# PIC32MZ2048EFM144 register map
Registers are 32-bit, access not given, reset 0x0 unless marked. A register's access mark holds for its fields unless they carry their own. Offsets are from the block's base; [hi:lo] are bit positions; {n}, {i} and the like mark numbered series; 'fields as' and 'values as' point back to an identical list.

## DMT — DMT peripheral
Base 0xBF800A00
0x00 DMTCON
  [15] ON
0x10 DMTPRECLR
  [15:8] STEP1
0x20 DMTCLR
  [7:0] STEP2
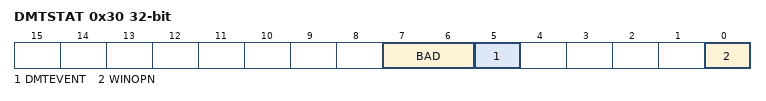
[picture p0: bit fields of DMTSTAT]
0x30 DMTSTAT
  [7:6] BAD, [5] DMTEVENT, [0] WINOPN
0x40 DMTCNT
  [31:0] COUNTER
0x60 DMTPSCNT
  [31:0] PSCNT
0x70 DMTPSINTV
  [31:0] PSINTV

## RTCC — RTCC peripheral
Base 0xBF800C00
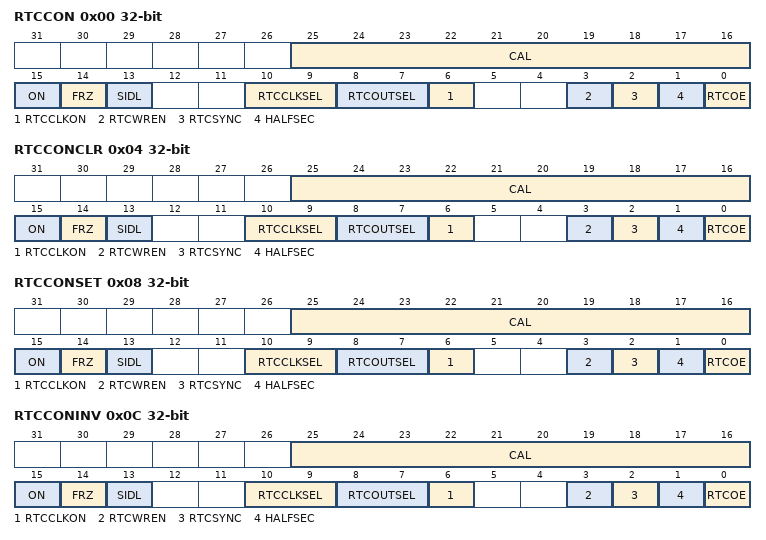
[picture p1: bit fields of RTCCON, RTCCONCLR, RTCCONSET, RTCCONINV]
0x00 RTCCON
  [25:16] CAL, [15] ON, [14] FRZ, [13] SIDL, [10:9] RTCCLKSEL, [8:7] RTCOUTSEL, [6] RTCCLKON, [3] RTCWREN, [2] RTCSYNC, [1] HALFSEC, [0] RTCOE
0x04 RTCCONCLR
  fields as RTCCON
0x08 RTCCONSET
  fields as RTCCON
0x0C RTCCONINV
  fields as RTCCON
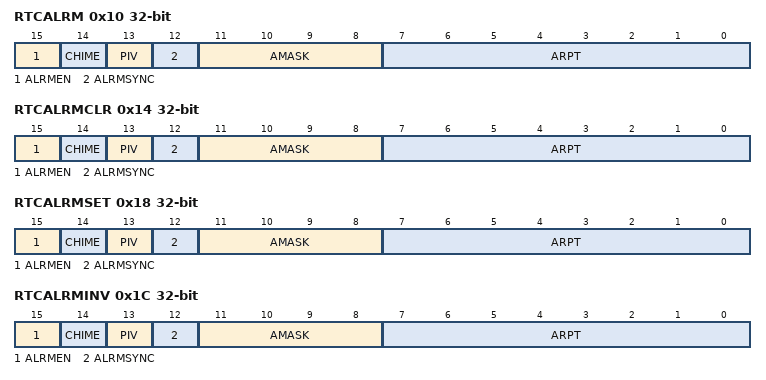
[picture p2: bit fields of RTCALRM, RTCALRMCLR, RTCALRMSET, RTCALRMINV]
0x10 RTCALRM
  [15] ALRMEN, [14] CHIME, [13] PIV, [12] ALRMSYNC, [11:8] AMASK, [7:0] ARPT
0x14 RTCALRMCLR
  fields as RTCALRM
0x18 RTCALRMSET
  fields as RTCALRM
0x1C RTCALRMINV
  fields as RTCALRM
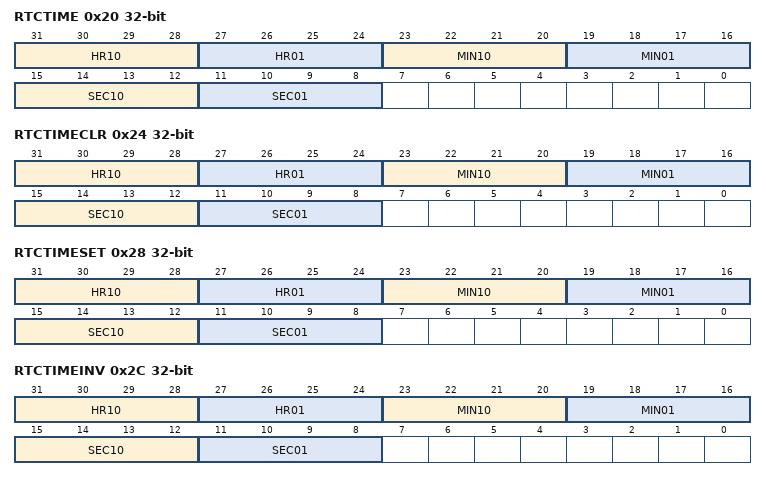
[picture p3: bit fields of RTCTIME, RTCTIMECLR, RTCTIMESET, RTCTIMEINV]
0x20 RTCTIME
  [31:28] HR10, [27:24] HR01, [23:20] MIN10, [19:16] MIN01, [15:12] SEC10, [11:8] SEC01
0x24 RTCTIMECLR
  fields as RTCTIME
0x28 RTCTIMESET
  fields as RTCTIME
0x2C RTCTIMEINV
  fields as RTCTIME
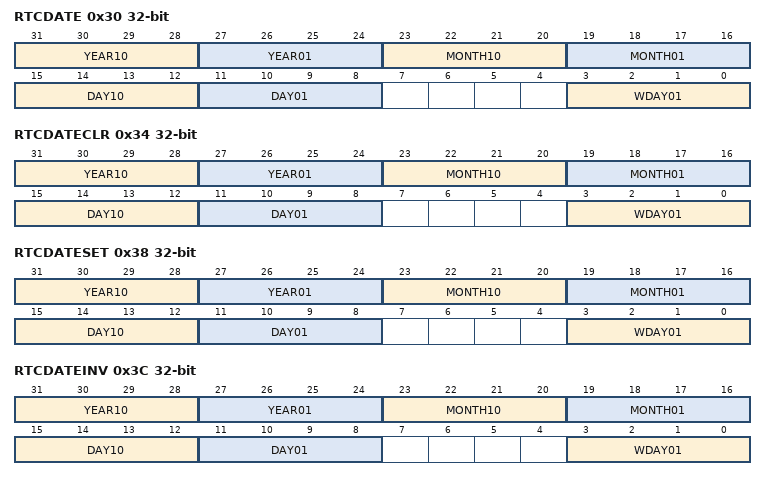
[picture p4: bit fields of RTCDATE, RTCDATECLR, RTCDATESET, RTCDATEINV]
0x30 RTCDATE
  [31:28] YEAR10, [27:24] YEAR01, [23:20] MONTH10, [19:16] MONTH01, [15:12] DAY10, [11:8] DAY01, [3:0] WDAY01
0x34 RTCDATECLR
  fields as RTCDATE
0x38 RTCDATESET
  fields as RTCDATE
0x3C RTCDATEINV
  fields as RTCDATE
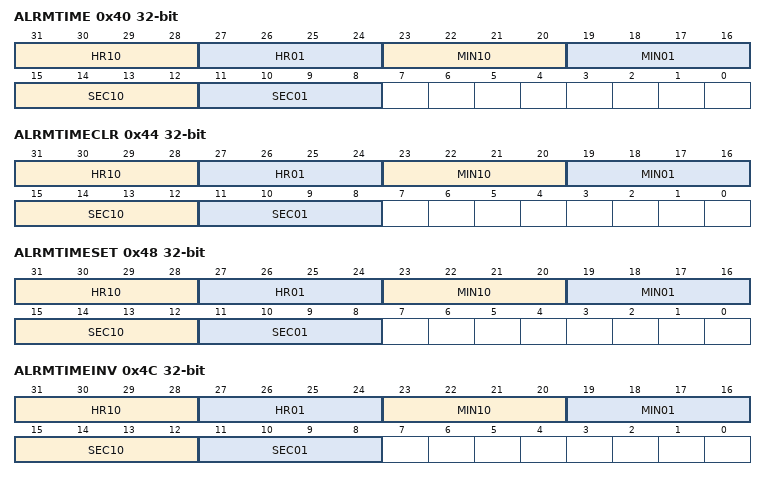
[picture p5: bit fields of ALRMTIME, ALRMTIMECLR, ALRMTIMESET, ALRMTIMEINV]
0x40 ALRMTIME
  fields as RTCTIME
0x44 ALRMTIMECLR
  fields as RTCTIME
0x48 ALRMTIMESET
  fields as RTCTIME
0x4C ALRMTIMEINV
  fields as RTCTIME
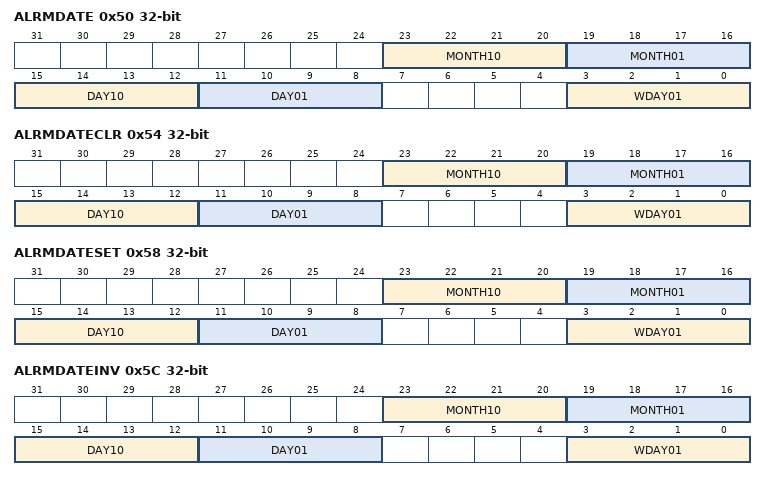
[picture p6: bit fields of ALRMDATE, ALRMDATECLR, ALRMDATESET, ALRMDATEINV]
0x50 ALRMDATE
  [23:20] MONTH10, [19:16] MONTH01, [15:12] DAY10, [11:8] DAY01, [3:0] WDAY01
0x54 ALRMDATECLR
  fields as ALRMDATE
0x58 ALRMDATESET
  fields as ALRMDATE
0x5C ALRMDATEINV
  fields as ALRMDATE

## CVR — CVR peripheral
Base 0xBF800E00
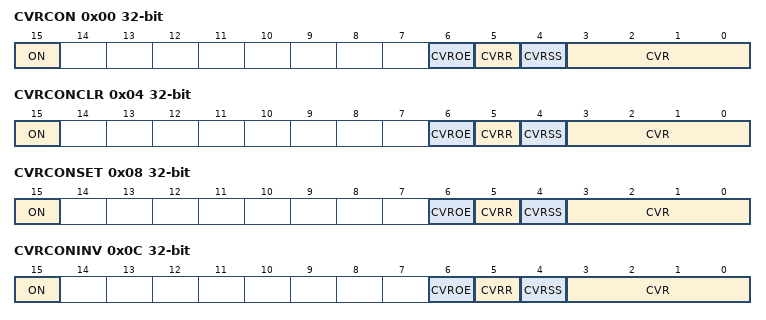
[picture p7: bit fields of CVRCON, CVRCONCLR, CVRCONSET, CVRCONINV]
0x00 CVRCON
  [15] ON, [6] CVROE, [5] CVRR, [4] CVRSS, [3:0] CVR
0x04 CVRCONCLR
  [15] ON, [6] CVROE, [5] CVRR, [4] CVRSS, [3:0] CVR
0x08 CVRCONSET
  [15] ON, [6] CVROE, [5] CVRR, [4] CVRSS, [3:0] CVR
0x0C CVRCONINV
  [15] ON, [6] CVROE, [5] CVRR, [4] CVRSS, [3:0] CVR

## ICD — ICD peripheral
Base 0xBF801130
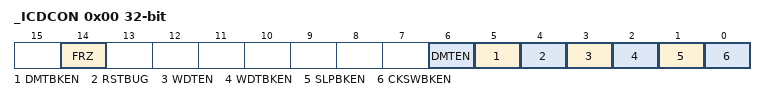
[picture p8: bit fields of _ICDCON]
0x00 _ICDCON
  [14] FRZ, [6] DMTEN, [5] DMTBKEN, [4] RSTBUG, [3] WDTEN, [2] WDTBKEN, [1] SLPBKEN, [0] CKSWBKEN

## _DDPSTAT — _DDPSTAT peripheral
Base 0xBF801140
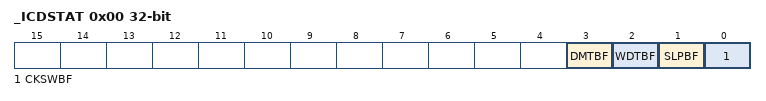
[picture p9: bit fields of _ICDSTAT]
0x00 _ICDSTAT
  [3] DMTBF, [2] WDTBF, [1] SLPBF, [0] CKSWBF

## CRU — CRU peripheral
Base 0xBF801200
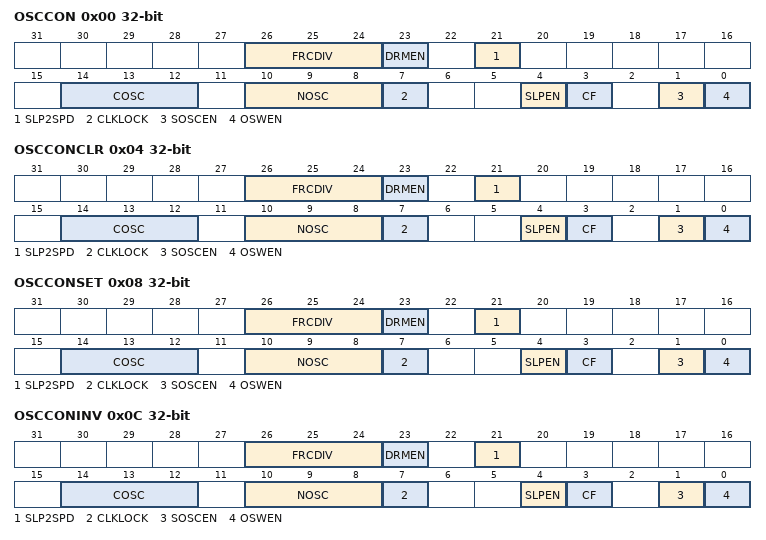
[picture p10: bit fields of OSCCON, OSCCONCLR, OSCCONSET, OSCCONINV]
0x00 OSCCON
  [26:24] FRCDIV, [23] DRMEN, [21] SLP2SPD, [14:12] COSC, [10:8] NOSC, [7] CLKLOCK, [4] SLPEN, [3] CF, [1] SOSCEN, [0] OSWEN
0x04 OSCCONCLR
  fields as OSCCON
0x08 OSCCONSET
  fields as OSCCON
0x0C OSCCONINV
  fields as OSCCON
0x10 OSCTUN
  [5:0] TUN
0x14 OSCTUNCLR
  [5:0] TUN
0x18 OSCTUNSET
  [5:0] TUN
0x1C OSCTUNINV
  [5:0] TUN
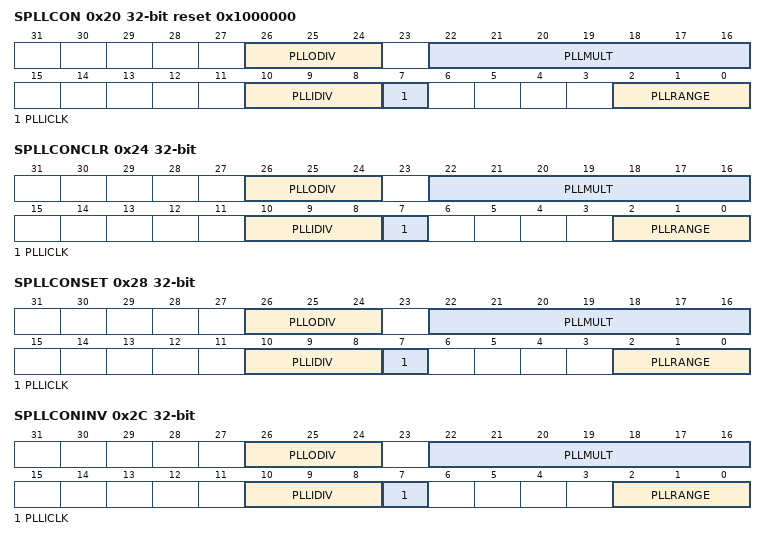
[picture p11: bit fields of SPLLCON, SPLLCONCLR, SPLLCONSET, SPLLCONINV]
0x20 SPLLCON reset 0x1000000
  [26:24] PLLODIV, [22:16] PLLMULT, [10:8] PLLIDIV, [7] PLLICLK, [2:0] PLLRANGE
0x24 SPLLCONCLR
  fields as SPLLCON
0x28 SPLLCONSET
  fields as SPLLCON
0x2C SPLLCONINV
  fields as SPLLCON
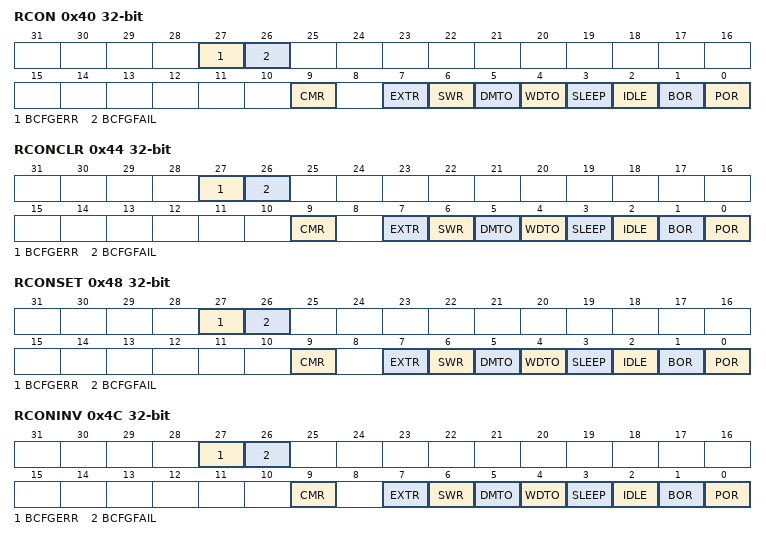
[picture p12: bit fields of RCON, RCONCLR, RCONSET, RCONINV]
0x40 RCON
  [27] BCFGERR, [26] BCFGFAIL, [9] CMR, [7] EXTR, [6] SWR, [5] DMTO, [4] WDTO, [3] SLEEP, [2] IDLE, [1] BOR, [0] POR
0x44 RCONCLR
  fields as RCON
0x48 RCONSET
  fields as RCON
0x4C RCONINV
  fields as RCON
0x50 RSWRST
  [0] SWRST
0x54 RSWRSTCLR
  [0] SWRST
0x58 RSWRSTSET
  [0] SWRST
0x5C RSWRSTINV
  [0] SWRST
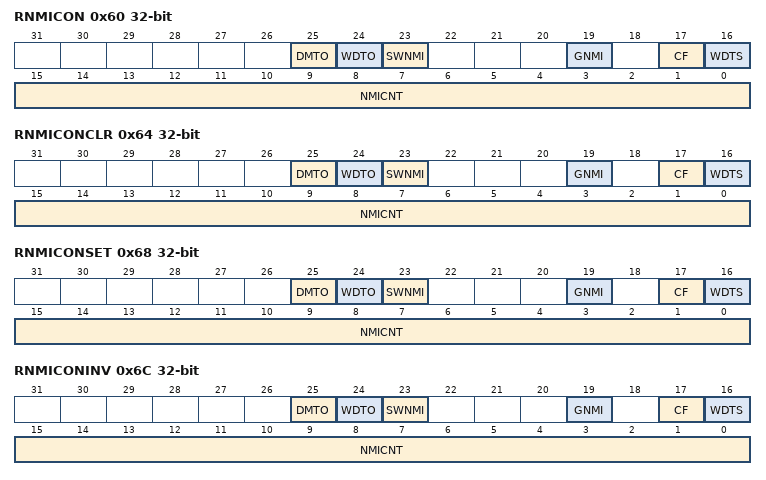
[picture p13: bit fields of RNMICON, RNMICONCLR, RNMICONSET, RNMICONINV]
0x60 RNMICON
  [25] DMTO, [24] WDTO, [23] SWNMI, [19] GNMI, [17] CF, [16] WDTS, [15:0] NMICNT
0x64 RNMICONCLR
  fields as RNMICON
0x68 RNMICONSET
  fields as RNMICON
0x6C RNMICONINV
  fields as RNMICON
0x70 PWRCON
  [0] VREGS
0x74 PWRCONCLR
  [0] VREGS
0x78 PWRCONSET
  [0] VREGS
0x7C PWRCONINV
  [0] VREGS
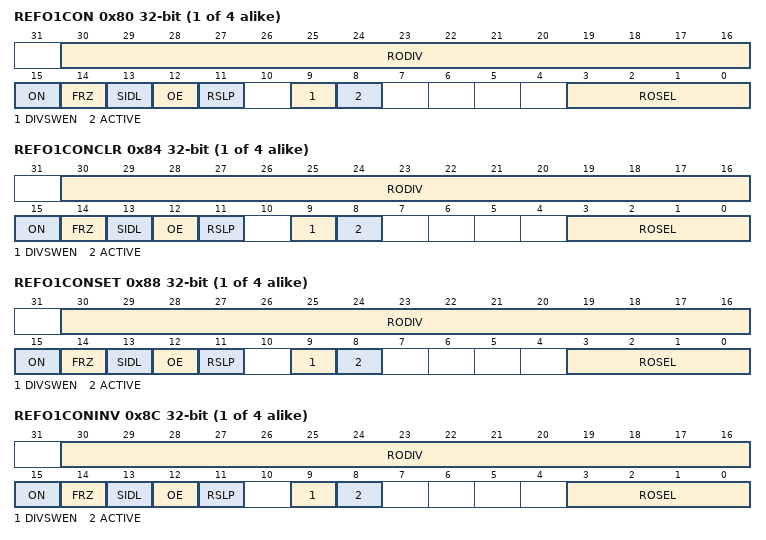
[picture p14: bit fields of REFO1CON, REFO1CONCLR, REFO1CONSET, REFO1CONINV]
{0x60+0x20*i} REFO{i}CON (i=1..4)
  [30:16] RODIV, [15] ON, [14] FRZ, [13] SIDL, [12] OE, [11] RSLP, [9] DIVSWEN, [8] ACTIVE, [3:0] ROSEL
{0x64+0x20*i} REFO{i}CONCLR (i=1..4)
  fields as REFO1CON
{0x68+0x20*i} REFO{i}CONSET (i=1..4)
  fields as REFO1CON
{0x6C+0x20*i} REFO{i}CONINV (i=1..4)
  fields as REFO1CON
{0x70+0x20*i} REFO{i}TRIM (i=1..4)
  [31:23] ROTRIM
{0x74+0x20*i} REFO{i}TRIMCLR (i=1..4)
  [31:23] ROTRIM
{0x78+0x20*i} REFO{i}TRIMSET (i=1..4)
  [31:23] ROTRIM
{0x7C+0x20*i} REFO{i}TRIMINV (i=1..4)
  [31:23] ROTRIM
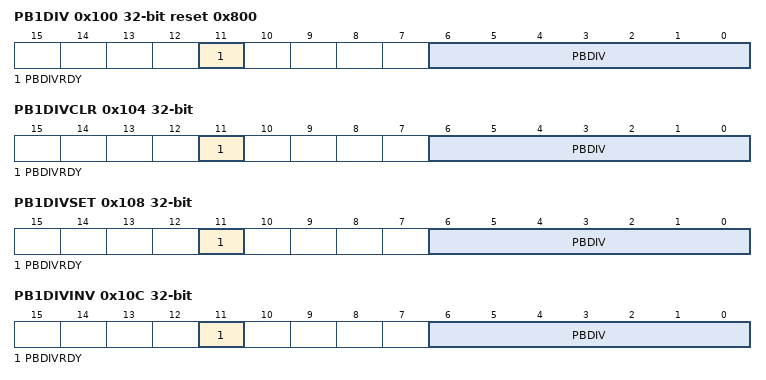
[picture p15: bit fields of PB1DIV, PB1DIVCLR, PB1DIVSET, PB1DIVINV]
0x100 PB1DIV reset 0x800
  [11] PBDIVRDY, [6:0] PBDIV
0x104 PB1DIVCLR
  [11] PBDIVRDY, [6:0] PBDIV
0x108 PB1DIVSET
  [11] PBDIVRDY, [6:0] PBDIV
0x10C PB1DIVINV
  [11] PBDIVRDY, [6:0] PBDIV
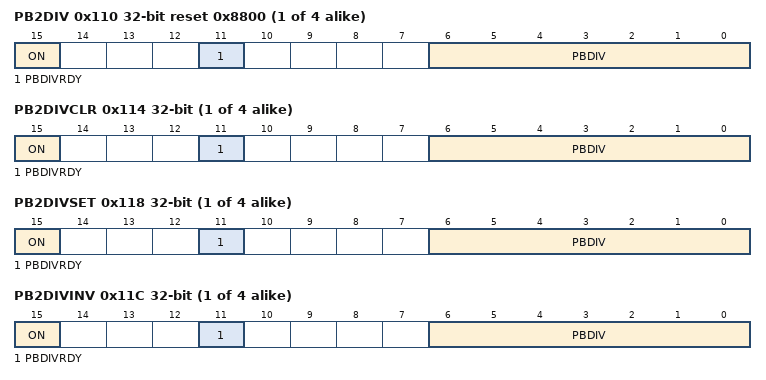
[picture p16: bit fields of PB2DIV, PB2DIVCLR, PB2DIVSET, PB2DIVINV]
{0xF0+0x10*i} PB{i}DIV reset 0x8800 (i=2..5)
  [15] ON, [11] PBDIVRDY, [6:0] PBDIV
{0xF4+0x10*i} PB{i}DIVCLR (i=2..5)
  [15] ON, [11] PBDIVRDY, [6:0] PBDIV
{0xF8+0x10*i} PB{i}DIVSET (i=2..5)
  [15] ON, [11] PBDIVRDY, [6:0] PBDIV
{0xFC+0x10*i} PB{i}DIVINV (i=2..5)
  [15] ON, [11] PBDIVRDY, [6:0] PBDIV
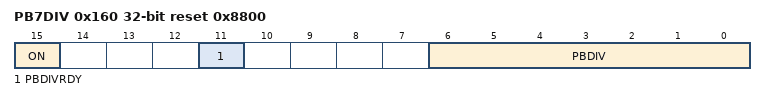
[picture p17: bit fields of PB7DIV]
0x160 PB7DIV reset 0x8800
  [15] ON, [11] PBDIVRDY, [6:0] PBDIV
0x164 PB7DIVCLR
  [15] ON, [11] PBDIVRDY, [6:0] PBDIV
0x168 PB7DIVSET
  [15] ON, [11] PBDIVRDY, [6:0] PBDIV
0x16C PB7DIVINV
  [15] ON, [11] PBDIVRDY, [6:0] PBDIV
0x170 PB8DIV reset 0x8800
  [15] ON, [11] PBDIVRDY, [6:0] PBDIV
0x174 PB8DIVCLR
  [15] ON, [11] PBDIVRDY, [6:0] PBDIV
0x178 PB8DIVSET
  [15] ON, [11] PBDIVRDY, [6:0] PBDIV
0x17C PB8DIVINV
  [15] ON, [11] PBDIVRDY, [6:0] PBDIV
0x1C0 SLEWCON
  [19:16] SYSDIV, [10:8] SLWDIV, [2] UPEN, [1] DNEN, [0] BUSY
0x1C4 SLEWCONCLR
  [19:16] SYSDIV, [10:8] SLWDIV, [2] UPEN, [1] DNEN, [0] BUSY
0x1C8 SLEWCONSET
  [19:16] SYSDIV, [10:8] SLWDIV, [2] UPEN, [1] DNEN, [0] BUSY
0x1CC SLEWCONINV
  [19:16] SYSDIV, [10:8] SLWDIV, [2] UPEN, [1] DNEN, [0] BUSY
0x1D0 CLKSTAT
  [5] LPRCRDY, [4] SOSCRDY, [2] POSCRDY, [1] SPDIVRDY, [0] FRCRDY
0x1D4 CLKSTATCLR
  [5] LPRCRDY, [4] SOSCRDY, [2] POSCRDY, [1] SPDIVRDY, [0] FRCRDY
0x1D8 CLKSTATSET
  [5] LPRCRDY, [4] SOSCRDY, [2] POSCRDY, [1] SPDIVRDY, [0] FRCRDY
0x1DC CLKSTATINV
  [5] LPRCRDY, [4] SOSCRDY, [2] POSCRDY, [1] SPDIVRDY, [0] FRCRDY
